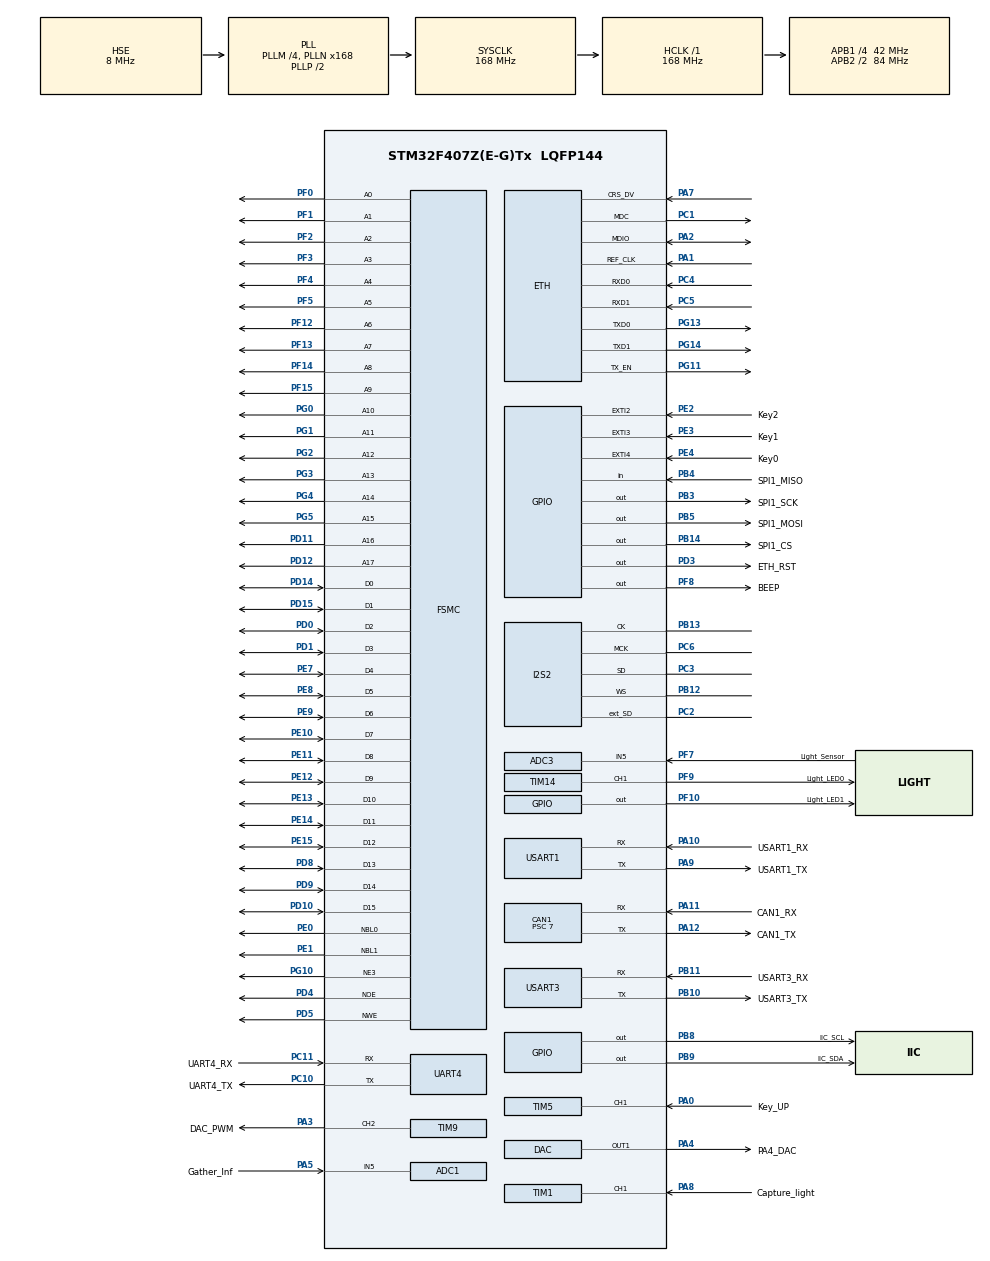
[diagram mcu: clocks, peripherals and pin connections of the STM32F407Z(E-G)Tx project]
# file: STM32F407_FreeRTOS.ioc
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ADC1.Channel-0\#ChannelRegularConversion=ADC_CHANNEL_5
ADC1.ClockPrescaler=ADC_CLOCK_SYNC_PCLK_DIV4
ADC1.ContinuousConvMode=ENABLE
ADC1.DMAContinuousRequests=ENABLE
ADC1.DataAlign=ADC_DATAALIGN_RIGHT
ADC1.DiscontinuousConvMode=DISABLE
ADC1.EOCSelection=ADC_EOC_SINGLE_CONV
ADC1.EnableAnalogWatchDog=false
ADC1.ExternalTrigConv=ADC_SOFTWARE_START
ADC1.ExternalTrigConvEdge=ADC_EXTERNALTRIGCONVEDGE_NONE
ADC1.InjNumberOfConversion=0
ADC1.NbrOfConversion=1
ADC1.NbrOfConversionFlag=1
ADC1.Rank-0\#ChannelRegularConversion=1
ADC1.Resolution=ADC_RESOLUTION_12B
ADC1.SamplingTime-0\#ChannelRegularConversion=ADC_SAMPLETIME_480CYCLES
ADC1.ScanConvMode=ENABLE
ADC1.master=1
ADC3.Channel-0\#ChannelRegularConversion=ADC_CHANNEL_5
ADC3.ClockPrescaler=ADC_CLOCK_SYNC_PCLK_DIV4
ADC3.ContinuousConvMode=ENABLE
ADC3.DMAContinuousRequests=ENABLE
ADC3.DataAlign=ADC_DATAALIGN_RIGHT
ADC3.DiscontinuousConvMode=DISABLE
ADC3.EOCSelection=ADC_EOC_SINGLE_CONV
ADC3.EnableAnalogWatchDog=false
ADC3.ExternalTrigConv=ADC_SOFTWARE_START
ADC3.ExternalTrigConvEdge=ADC_EXTERNALTRIGCONVEDGE_NONE
ADC3.InjNumberOfConversion=0
ADC3.NbrOfConversion=1
ADC3.NbrOfConversionFlag=1
ADC3.Rank-0\#ChannelRegularConversion=1
ADC3.Resolution=ADC_RESOLUTION_10B
ADC3.SamplingTime-0\#ChannelRegularConversion=ADC_SAMPLETIME_480CYCLES
ADC3.ScanConvMode=ENABLE
CAN1.ABOM=DISABLE
CAN1.AWUM=DISABLE
CAN1.BS1=CAN_BS1_5TQ
CAN1.BS2=CAN_BS2_6TQ
CAN1.CalculateTimeQuantum=166.66666666666669
CAN1.Mode=CAN_MODE_NORMAL
CAN1.NART=ENABLE
CAN1.Prescaler=7
CAN1.RFLM=DISABLE
CAN1.TTCM=DISABLE
CAN1.TXFP=DISABLE
DAC.DAC_OutputBuffer=DAC_OUTPUTBUFFER_DISABLE
Dma.ADC1.1.Direction=DMA_PERIPH_TO_MEMORY
Dma.ADC1.1.FIFOMode=DMA_FIFOMODE_DISABLE
Dma.ADC1.1.Instance=DMA2_Stream4
Dma.ADC1.1.MemDataAlignment=DMA_MDATAALIGN_HALFWORD
Dma.ADC1.1.MemInc=DMA_MINC_ENABLE
Dma.ADC1.1.Mode=DMA_NORMAL
Dma.ADC1.1.PeriphDataAlignment=DMA_PDATAALIGN_HALFWORD
Dma.ADC1.1.PeriphInc=DMA_PINC_DISABLE
Dma.ADC1.1.Priority=DMA_PRIORITY_LOW
Dma.ADC3.2.Direction=DMA_PERIPH_TO_MEMORY
Dma.ADC3.2.FIFOMode=DMA_FIFOMODE_DISABLE
Dma.ADC3.2.Instance=DMA2_Stream0
Dma.ADC3.2.MemDataAlignment=DMA_MDATAALIGN_HALFWORD
Dma.ADC3.2.MemInc=DMA_MINC_ENABLE
Dma.ADC3.2.Mode=DMA_CIRCULAR
Dma.ADC3.2.PeriphDataAlignment=DMA_PDATAALIGN_HALFWORD
Dma.ADC3.2.PeriphInc=DMA_PINC_DISABLE
Dma.ADC3.2.Priority=DMA_PRIORITY_LOW
Dma.DAC1.0.Direction=DMA_MEMORY_TO_PERIPH
Dma.DAC1.0.FIFOMode=DMA_FIFOMODE_DISABLE
Dma.DAC1.0.Instance=DMA1_Stream5
Dma.DAC1.0.MemDataAlignment=DMA_MDATAALIGN_WORD
Dma.DAC1.0.MemInc=DMA_MINC_ENABLE
Dma.DAC1.0.Mode=DMA_CIRCULAR
Dma.DAC1.0.PeriphDataAlignment=DMA_PDATAALIGN_WORD
Dma.DAC1.0.PeriphInc=DMA_PINC_DISABLE
Dma.DAC1.0.Priority=DMA_PRIORITY_LOW
Dma.I2S2_EXT_RX.4.Direction=DMA_PERIPH_TO_MEMORY
Dma.I2S2_EXT_RX.4.FIFOMode=DMA_FIFOMODE_DISABLE
Dma.I2S2_EXT_RX.4.Instance=DMA1_Stream3
Dma.I2S2_EXT_RX.4.MemDataAlignment=DMA_MDATAALIGN_HALFWORD
Dma.I2S2_EXT_RX.4.MemInc=DMA_MINC_ENABLE
Dma.I2S2_EXT_RX.4.Mode=DMA_CIRCULAR
Dma.I2S2_EXT_RX.4.PeriphDataAlignment=DMA_PDATAALIGN_HALFWORD
Dma.I2S2_EXT_RX.4.PeriphInc=DMA_PINC_DISABLE
Dma.I2S2_EXT_RX.4.Priority=DMA_PRIORITY_HIGH
Dma.Request0=DAC1
Dma.Request1=ADC1
Dma.Request2=ADC3
Dma.Request3=SPI2_TX
Dma.Request4=I2S2_EXT_RX
Dma.Request5=USART1_RX
Dma.Request6=USART3_RX
Dma.Request7=UART4_RX
Dma.SPI2_TX.3.Direction=DMA_MEMORY_TO_PERIPH
Dma.SPI2_TX.3.FIFOMode=DMA_FIFOMODE_DISABLE
Dma.SPI2_TX.3.Instance=DMA1_Stream4
Dma.SPI2_TX.3.MemDataAlignment=DMA_MDATAALIGN_HALFWORD
Dma.SPI2_TX.3.MemInc=DMA_MINC_ENABLE
Dma.SPI2_TX.3.Mode=DMA_CIRCULAR
Dma.SPI2_TX.3.PeriphDataAlignment=DMA_PDATAALIGN_HALFWORD
Dma.SPI2_TX.3.PeriphInc=DMA_PINC_DISABLE
Dma.SPI2_TX.3.Priority=DMA_PRIORITY_HIGH
Dma.UART4_RX.7.Direction=DMA_PERIPH_TO_MEMORY
Dma.UART4_RX.7.FIFOMode=DMA_FIFOMODE_DISABLE
Dma.UART4_RX.7.Instance=DMA1_Stream2
Dma.UART4_RX.7.MemDataAlignment=DMA_MDATAALIGN_BYTE
Dma.UART4_RX.7.MemInc=DMA_MINC_ENABLE
Dma.UART4_RX.7.Mode=DMA_NORMAL
Dma.UART4_RX.7.PeriphDataAlignment=DMA_PDATAALIGN_BYTE
Dma.UART4_RX.7.PeriphInc=DMA_PINC_DISABLE
Dma.UART4_RX.7.Priority=DMA_PRIORITY_LOW
Dma.USART1_RX.5.Direction=DMA_PERIPH_TO_MEMORY
Dma.USART1_RX.5.FIFOMode=DMA_FIFOMODE_DISABLE
Dma.USART1_RX.5.Instance=DMA2_Stream2
Dma.USART1_RX.5.MemDataAlignment=DMA_MDATAALIGN_BYTE
Dma.USART1_RX.5.MemInc=DMA_MINC_ENABLE
Dma.USART1_RX.5.Mode=DMA_NORMAL
Dma.USART1_RX.5.PeriphDataAlignment=DMA_PDATAALIGN_BYTE
Dma.USART1_RX.5.PeriphInc=DMA_PINC_DISABLE
Dma.USART1_RX.5.Priority=DMA_PRIORITY_LOW
Dma.USART3_RX.6.Direction=DMA_PERIPH_TO_MEMORY
Dma.USART3_RX.6.FIFOMode=DMA_FIFOMODE_DISABLE
Dma.USART3_RX.6.Instance=DMA1_Stream1
Dma.USART3_RX.6.MemDataAlignment=DMA_MDATAALIGN_BYTE
Dma.USART3_RX.6.MemInc=DMA_MINC_ENABLE
Dma.USART3_RX.6.Mode=DMA_NORMAL
Dma.USART3_RX.6.PeriphDataAlignment=DMA_PDATAALIGN_BYTE
Dma.USART3_RX.6.PeriphInc=DMA_PINC_DISABLE
Dma.USART3_RX.6.Priority=DMA_PRIORITY_LOW
ETH.AutoNegotiation=ETH_AUTONEGOTIATION_ENABLE
ETH.MediaInterface=ETH_MEDIA_INTERFACE_RMII
ETH.PHY_DUPLEX_STATUS=0x0010
ETH.PHY_Name_RMII=userPHY
ETH.PHY_SPEED_STATUS=0x0004
ETH.PHY_SR=0x1F
ETH.PHY_User_Name=LAN8720
ETH.PhyAddress=0
FREERTOS.Queues01=USMARTQueue,8,usmart_receiveSTR,0,Dynamic,NULL,NULL
FREERTOS.Tasks01=defaultTask,0,128,StartDefaultTask,Default,NULL,Dynamic,NULL,NULL;ThreadTask02,0,128,USART1ManageFuc,Default,NULL,Dynamic,NULL,NULL;ThreadTask03,-3,128,USMARTManageFuc,Default,NULL,Dynamic,NULL,NULL;ThreadTask04,-3,128,J1939ManageFuc,Default,NULL,Dynamic,NULL,NULL;ThreadTask05,-3,128,LwipManageFuc,Default,NULL,Dynamic,NULL,NULL
FSMC.AddressSetupTime1=0
FSMC.BusTurnAroundDuration1=0
FSMC.DataSetupTime1=6
FSMC.WriteOperation1=FSMC_WRITE_OPERATION_ENABLE
I2S2.AudioFreq=I2S_AUDIOFREQ_8K
I2S2.CPOL=I2S_CPOL_LOW
I2S2.DataFormat=I2S_DATAFORMAT_24B
I2S2.ErrorAudioFreq=-0.12 %
I2S2.FullDuplexMode=I2S_FULLDUPLEXMODE_ENABLE
I2S2.Instance=SPI$Index
I2S2.RealAudioFreq=7.99 KHz
I2S2.VirtualMode=I2S_MODE_MASTER
LWIP.GATEWAY_ADDRESS=192.168.000.001
LWIP.IP_ADDRESS=192.168.000.030
LWIP.LWIP_DHCP=0
LWIP.LWIP_IPV6=0
LWIP.LWIP_UDP=1
LWIP.MEMP_NUM_UDP_PCB=4
LWIP.MEM_SIZE=1600
LWIP.NETMASK_ADDRESS=255.255.255.000
LWIP.TCP_WND=2144
LWIP.Version=v2.0.3_Cube
Mcu.Family=STM32F4
Mcu.Name=STM32F407Z(E-G)Tx
Mcu.Package=LQFP144
NVIC.CAN1_RX0_IRQn=true\:5\:0\:false\:false\:true\:true\:true
NVIC.DMA1_Stream1_IRQn=true\:5\:0\:false\:false\:true\:true\:false
NVIC.DMA1_Stream2_IRQn=true\:10\:0\:true\:false\:true\:true\:false
NVIC.DMA1_Stream3_IRQn=true\:5\:0\:false\:false\:true\:true\:false
NVIC.DMA1_Stream4_IRQn=true\:5\:0\:false\:false\:true\:true\:false
NVIC.DMA1_Stream5_IRQn=true\:5\:0\:false\:false\:true\:true\:false
NVIC.DMA2_Stream0_IRQn=true\:5\:0\:false\:false\:true\:true\:false
NVIC.DMA2_Stream2_IRQn=true\:5\:0\:false\:false\:true\:true\:false
NVIC.DMA2_Stream4_IRQn=true\:5\:0\:false\:false\:true\:true\:false
NVIC.ETH_IRQn=true\:12\:0\:true\:false\:true\:true\:false
NVIC.EXTI2_IRQn=true\:12\:0\:true\:false\:true\:true\:true
NVIC.EXTI3_IRQn=true\:12\:0\:true\:false\:true\:true\:true
NVIC.EXTI4_IRQn=true\:12\:0\:true\:false\:true\:true\:true
NVIC.HASH_RNG_IRQn=true\:15\:0\:true\:false\:true\:true\:true
NVIC.PriorityGroup=NVIC_PRIORITYGROUP_4
NVIC.RTC_Alarm_IRQn=true\:15\:0\:true\:false\:true\:true\:true
NVIC.TIM1_CC_IRQn=true\:6\:0\:true\:false\:true\:true\:true
NVIC.TIM1_UP_TIM10_IRQn=true\:6\:0\:true\:false\:true\:true\:true
NVIC.TIM2_IRQn=true\:6\:0\:true\:false\:true\:true\:true
NVIC.TIM3_IRQn=true\:0\:0\:false\:false\:true\:false\:false
NVIC.TIM4_IRQn=true\:7\:0\:true\:false\:true\:true\:true
NVIC.TIM5_IRQn=true\:14\:0\:true\:false\:true\:true\:true
NVIC.TIM7_IRQn=true\:5\:0\:true\:false\:true\:true\:true
NVIC.TIM8_TRG_COM_TIM14_IRQn=true\:5\:0\:false\:false\:true\:true\:true
NVIC.TimeBase=TIM3_IRQn
NVIC.TimeBaseIP=TIM3
NVIC.UART4_IRQn=true\:13\:0\:true\:false\:true\:true\:true
NVIC.USART1_IRQn=true\:6\:0\:true\:false\:true\:true\:true
NVIC.USART3_IRQn=true\:7\:0\:true\:false\:true\:true\:true
PA0-WKUP.GPIO_Label=Key_UP
PA0-WKUP.GPIO_PuPd=GPIO_NOPULL
PA0-WKUP.GPIO_Speed=GPIO_SPEED_FREQ_LOW
PA0-WKUP.Signal=S_TIM5_CH1
PA1.Mode=RMII
PA1.Signal=ETH_REF_CLK
PA10.GPIO_Label=USART1_RX
PA10.GPIO_Speed=GPIO_SPEED_FREQ_HIGH
PA10.Mode=Asynchronous
PA10.Signal=USART1_RX
PA11.GPIO_Label=CAN1_RX
PA11.GPIO_PuPd=GPIO_PULLUP
PA11.GPIO_Speed=GPIO_SPEED_FREQ_HIGH
PA11.Mode=Master
PA11.Signal=CAN1_RX
PA12.GPIO_Label=CAN1_TX
PA12.GPIO_PuPd=GPIO_PULLUP
PA12.GPIO_Speed=GPIO_SPEED_FREQ_HIGH
PA12.Mode=Master
PA12.Signal=CAN1_TX
PA13.Mode=Serial_Wire
PA13.Signal=SYS_JTMS-SWDIO
PA14.Mode=Serial_Wire
PA14.Signal=SYS_JTCK-SWCLK
PA2.Mode=RMII
PA2.Signal=ETH_MDIO
PA3.GPIO_Label=DAC_PWM
PA3.Signal=S_TIM9_CH2
PA4.GPIO_Label=PA4_DAC
PA4.Signal=SharedAnalog_PA4
PA5.GPIO_Label=Gather_Inf
PA5.Signal=SharedAnalog_PA5
PA7.Mode=RMII
PA7.Signal=ETH_CRS_DV
PA8.GPIO_Label=Capture_light
PA8.GPIO_PuPd=GPIO_PULLUP
PA8.GPIO_Speed=GPIO_SPEED_FREQ_HIGH
PA8.Signal=S_TIM1_CH1
PA9.GPIO_Label=USART1_TX
PA9.GPIO_Speed=GPIO_SPEED_FREQ_HIGH
PA9.Mode=Asynchronous
PA9.Signal=USART1_TX
PB10.GPIO_Label=USART3_TX
PB10.GPIO_Speed=GPIO_SPEED_FREQ_HIGH
PB10.Mode=Asynchronous
PB10.Signal=USART3_TX
PB11.GPIO_Label=USART3_RX
PB11.GPIO_Speed=GPIO_SPEED_FREQ_HIGH
PB11.Mode=Asynchronous
PB11.Signal=USART3_RX
PB12.GPIO_PuPd=GPIO_PULLUP
PB12.GPIO_Speed=GPIO_SPEED_FREQ_HIGH
PB12.Mode=Full_Duplex_Master
PB12.Signal=I2S2_WS
PB13.GPIO_PuPd=GPIO_PULLUP
PB13.GPIO_Speed=GPIO_SPEED_FREQ_HIGH
PB13.Mode=Full_Duplex_Master
PB13.Signal=I2S2_CK
PB14.GPIO_Label=SPI1_CS
PB14.GPIO_PuPd=GPIO_PULLUP
PB14.GPIO_Speed=GPIO_SPEED_FREQ_HIGH
PB14.Signal=GPIO_Output
PB3.GPIO_Label=SPI1_SCK
PB3.GPIO_PuPd=GPIO_PULLUP
PB3.GPIO_Speed=GPIO_SPEED_FREQ_HIGH
PB3.Signal=GPIO_Output
PB4.GPIO_Label=SPI1_MISO
PB4.GPIO_PuPd=GPIO_PULLUP
PB4.Signal=GPIO_Input
PB5.GPIO_Label=SPI1_MOSI
PB5.GPIO_PuPd=GPIO_PULLUP
PB5.GPIO_Speed=GPIO_SPEED_FREQ_HIGH
PB5.Signal=GPIO_Output
PB8.GPIO_Label=IIC_SCL
PB8.GPIO_ModeDefaultOutputPP=GPIO_MODE_OUTPUT_PP
PB8.GPIO_PuPd=GPIO_PULLUP
PB8.GPIO_Speed=GPIO_SPEED_FREQ_HIGH
PB8.Signal=GPIO_Output
PB9.GPIO_Label=IIC_SDA
PB9.GPIO_PuPd=GPIO_PULLUP
PB9.GPIO_Speed=GPIO_SPEED_FREQ_HIGH
PB9.Signal=GPIO_Output
PC1.Mode=RMII
PC1.Signal=ETH_MDC
PC10.GPIO_Label=UART4_TX
PC10.GPIO_Speed=GPIO_SPEED_FREQ_HIGH
PC10.Mode=Asynchronous
PC10.Signal=UART4_TX
PC11.GPIO_Label=UART4_RX
PC11.GPIO_Speed=GPIO_SPEED_FREQ_HIGH
PC11.Mode=Asynchronous
PC11.Signal=UART4_RX
PC14-OSC32_IN.Mode=LSE-External-Oscillator
PC14-OSC32_IN.Signal=RCC_OSC32_IN
PC15-OSC32_OUT.Mode=LSE-External-Oscillator
PC15-OSC32_OUT.Signal=RCC_OSC32_OUT
PC2.Mode=Full_Duplex_Master
PC2.Signal=I2S2_ext_SD
PC3.Mode=Full_Duplex_Master
PC3.Signal=I2S2_SD
PC4.Mode=RMII
PC4.Signal=ETH_RXD0
PC5.Mode=RMII
PC5.Signal=ETH_RXD1
PC6.Mode=Master_Clock_Activated
PC6.Signal=I2S2_MCK
PD0.Signal=FSMC_D2_DA2
PD1.Signal=FSMC_D3_DA3
PD10.Signal=FSMC_D15_DA15
PD11.Signal=FSMC_A16_CLE
PD12.Signal=FSMC_A17_ALE
PD14.Signal=FSMC_D0_DA0
PD15.Signal=FSMC_D1_DA1
PD3.GPIO_Label=ETH_RST
PD3.Signal=GPIO_Output
PD4.Signal=FSMC_NOE
PD5.Signal=FSMC_NWE
PD8.Signal=FSMC_D13_DA13
PD9.Signal=FSMC_D14_DA14
PE0.Signal=FSMC_NBL0
PE1.Signal=FSMC_NBL1
PE10.Signal=FSMC_D7_DA7
PE11.Signal=FSMC_D8_DA8
PE12.Signal=FSMC_D9_DA9
PE13.Signal=FSMC_D10_DA10
PE14.Signal=FSMC_D11_DA11
PE15.Signal=FSMC_D12_DA12
PE2.GPIO_Label=Key2
PE2.GPIO_ModeDefaultEXTI=GPIO_MODE_IT_FALLING
PE2.GPIO_PuPd=GPIO_PULLUP
PE2.Signal=GPXTI2
PE3.GPIO_Label=Key1
PE3.GPIO_ModeDefaultEXTI=GPIO_MODE_IT_FALLING
PE3.GPIO_PuPd=GPIO_PULLUP
PE3.Signal=GPXTI3
PE4.GPIO_Label=Key0
PE4.GPIO_ModeDefaultEXTI=GPIO_MODE_IT_FALLING
PE4.GPIO_PuPd=GPIO_PULLUP
PE4.Signal=GPXTI4
PE7.Signal=FSMC_D4_DA4
PE8.Signal=FSMC_D5_DA5
PE9.Signal=FSMC_D6_DA6
PF0.Signal=FSMC_A0
PF1.Signal=FSMC_A1
PF10.GPIO_Label=Light_LED1
PF10.GPIO_PuPd=GPIO_PULLDOWN
PF10.Signal=GPIO_Output
PF12.Signal=FSMC_A6
PF13.Signal=FSMC_A7
PF14.Signal=FSMC_A8
PF15.Signal=FSMC_A9
PF2.Signal=FSMC_A2
PF3.Signal=FSMC_A3
PF4.Signal=FSMC_A4
PF5.Signal=FSMC_A5
PF7.GPIO_Label=Light_Sensor
PF7.Signal=SharedAnalog_PF7
PF8.GPIO_Label=BEEP
PF8.GPIO_Speed=GPIO_SPEED_FREQ_HIGH
PF8.Signal=GPIO_Output
PF9.GPIO_Label=Light_LED0
PF9.GPIO_PuPd=GPIO_PULLDOWN
PF9.Signal=S_TIM14_CH1
PG0.Signal=FSMC_A10
PG1.Signal=FSMC_A11
PG10.Mode=NorPsramChipSelect3_1
PG10.Signal=FSMC_NE3
PG11.Mode=RMII
PG11.Signal=ETH_TX_EN
PG13.Mode=RMII
PG13.Signal=ETH_TXD0
PG14.Mode=RMII
PG14.Signal=ETH_TXD1
PG2.Signal=FSMC_A12
PG3.Signal=FSMC_A13
PG4.Signal=FSMC_A14
PG5.Signal=FSMC_A15
PH0-OSC_IN.Mode=HSE-External-Oscillator
PH0-OSC_IN.Signal=RCC_OSC_IN
PH1-OSC_OUT.Mode=HSE-External-Oscillator
PH1-OSC_OUT.Signal=RCC_OSC_OUT
ProjectManager.HeapSize=0x200
ProjectManager.StackSize=0x400
ProjectManager.TargetToolchain=EWARM V8
RCC.48MHZClocksFreq_Value=48000000
RCC.AHBFreq_Value=168000000
RCC.APB1CLKDivider=RCC_HCLK_DIV4
RCC.APB1Freq_Value=42000000
RCC.APB1TimFreq_Value=84000000
RCC.APB2CLKDivider=RCC_HCLK_DIV2
RCC.APB2Freq_Value=84000000
RCC.APB2TimFreq_Value=168000000
RCC.CortexFreq_Value=168000000
RCC.HCLKFreq_Value=168000000
RCC.HSE_VALUE=8000000
RCC.HSI_VALUE=16000000
RCC.PLLI2SN=135
RCC.PLLI2SR=6
RCC.PLLM=4
RCC.PLLN=168
RCC.PLLQ=7
RCC.PLLSourceVirtual=RCC_PLLSOURCE_HSE
RCC.RCC_RTC_Clock_Source=RCC_RTCCLKSOURCE_LSI
RCC.RCC_RTC_Clock_SourceVirtual=RCC_RTCCLKSOURCE_LSE
RCC.SYSCLKFreq_VALUE=168000000
RCC.SYSCLKSource=RCC_SYSCLKSOURCE_PLLCLK
RCC.VCOOutputFreq_Value=336000000
RTC.Alarm=RTC_ALARM_A
RTC.AlarmDateWeekDaySel=RTC_ALARMDATEWEEKDAYSEL_WEEKDAY
RTC.AlarmSubSecondMask=RTC_ALARMSUBSECONDMASK_NONE
RTC.Date=16
RTC.Hours=22
RTC.Hours_A=15
RTC.Minutes=42
RTC.Minutes_A=18
RTC.Seconds=55
RTC.Seconds_A=23
RTC.WeekDay=RTC_WEEKDAY_WEDNESDAY
RTC.Year=21
SH.FSMC_A0.0=FSMC_A0,18b-a1
SH.FSMC_A1.0=FSMC_A1,18b-a1
SH.FSMC_A10.0=FSMC_A10,18b-a1
SH.FSMC_A11.0=FSMC_A11,18b-a1
SH.FSMC_A12.0=FSMC_A12,18b-a1
SH.FSMC_A13.0=FSMC_A13,18b-a1
SH.FSMC_A14.0=FSMC_A14,18b-a1
SH.FSMC_A15.0=FSMC_A15,18b-a1
SH.FSMC_A16_CLE.0=FSMC_A16,18b-a1
SH.FSMC_A17_ALE.0=FSMC_A17,18b-a1
SH.FSMC_A2.0=FSMC_A2,18b-a1
SH.FSMC_A3.0=FSMC_A3,18b-a1
SH.FSMC_A4.0=FSMC_A4,18b-a1
SH.FSMC_A5.0=FSMC_A5,18b-a1
SH.FSMC_A6.0=FSMC_A6,18b-a1
SH.FSMC_A7.0=FSMC_A7,18b-a1
SH.FSMC_A8.0=FSMC_A8,18b-a1
SH.FSMC_A9.0=FSMC_A9,18b-a1
SH.FSMC_D0_DA0.0=FSMC_D0,16b-d1
SH.FSMC_D10_DA10.0=FSMC_D10,16b-d1
SH.FSMC_D11_DA11.0=FSMC_D11,16b-d1
SH.FSMC_D12_DA12.0=FSMC_D12,16b-d1
SH.FSMC_D13_DA13.0=FSMC_D13,16b-d1
SH.FSMC_D14_DA14.0=FSMC_D14,16b-d1
SH.FSMC_D15_DA15.0=FSMC_D15,16b-d1
SH.FSMC_D1_DA1.0=FSMC_D1,16b-d1
SH.FSMC_D2_DA2.0=FSMC_D2,16b-d1
SH.FSMC_D3_DA3.0=FSMC_D3,16b-d1
SH.FSMC_D4_DA4.0=FSMC_D4,16b-d1
SH.FSMC_D5_DA5.0=FSMC_D5,16b-d1
SH.FSMC_D6_DA6.0=FSMC_D6,16b-d1
SH.FSMC_D7_DA7.0=FSMC_D7,16b-d1
SH.FSMC_D8_DA8.0=FSMC_D8,16b-d1
SH.FSMC_D9_DA9.0=FSMC_D9,16b-d1
SH.FSMC_NBL0.0=FSMC_NBL0,2ByteEnable1
SH.FSMC_NBL1.0=FSMC_NBL1,2ByteEnable1
SH.FSMC_NOE.0=FSMC_NOE,Sram1
SH.FSMC_NWE.0=FSMC_NWE,Sram1
SH.S_TIM14_CH1.0=TIM14_CH1,PWM Generation1 CH1
SH.S_TIM1_CH1.0=TIM1_CH1,Input_Capture1_from_TI1
SH.S_TIM5_CH1.0=TIM5_CH1,Input_Capture1_from_TI1
SH.S_TIM9_CH2.0=TIM9_CH2,PWM Generation2 CH2
SH.SharedAnalog_PA4.0=GPIO_Analog
SH.SharedAnalog_PA4.1=DAC_OUT1,DAC_OUT1
SH.SharedAnalog_PA5.0=GPIO_Analog
SH.SharedAnalog_PA5.1=ADC1_IN5,IN5
SH.SharedAnalog_PF7.0=GPIO_Analog
SH.SharedAnalog_PF7.1=ADC3_IN5,IN5
TIM1.Channel-Input_Capture1_from_TI1=TIM_CHANNEL_1
TIM1.ICFilter_CH1=0x03
TIM1.Period=10000
TIM1.Prescaler=179
TIM14.Channel=TIM_CHANNEL_1
TIM14.OCPolarity_1=TIM_OCPOLARITY_LOW
TIM14.Period=500
TIM14.Prescaler=42
TIM2.Channel-Input_Capture1_from_TI1=TIM_CHANNEL_1
TIM2.Period=0xFFFFFFFF
TIM2.Prescaler=1
TIM2.TIM_MasterOutputTrigger=TIM_TRGO_UPDATE
TIM4.Period=1000
TIM4.Prescaler=8400-1
TIM5.Channel-Input_Capture1_from_TI1=TIM_CHANNEL_1
TIM5.Period=0xFFFFFFFF
TIM5.Prescaler=84
TIM5.TIM_MasterOutputTrigger=TIM_TRGO_UPDATE
TIM7.Period=1
TIM7.Prescaler=84-1
TIM9.Channel-PWM\ Generation2\ CH2=TIM_CHANNEL_2
TIM9.Period=255
TIM9.Prescaler=1
UART4.VirtualMode=Asynchronous
USART1.OverSampling=UART_OVERSAMPLING_16
USART1.VirtualMode=VM_ASYNC
USART3.VirtualMode=VM_ASYNC
VP_FREERTOS_VS_ENABLE.Mode=Enabled
VP_LWIP_VS_Enabled.Mode=Enabled
VP_RNG_VS_RNG.Mode=RNG_Activate
VP_RTC_VS_RTC_Activate.Mode=RTC_Enabled
VP_RTC_VS_RTC_Alarm_A_Intern.Mode=Alarm A
VP_RTC_VS_RTC_Calendar.Mode=RTC_Calendar
VP_SYS_VS_tim3.Mode=TIM3
VP_TIM14_VS_ClockSourceINT.Mode=Enable_Timer
VP_TIM1_VS_ClockSourceINT.Mode=Internal
VP_TIM1_VS_ClockSourceITR.Mode=TriggerSource_ITR0
VP_TIM2_VS_ClockSourceINT.Mode=Internal
VP_TIM2_VS_ClockSourceITR.Mode=TriggerSource_ITR0
VP_TIM4_VS_ClockSourceINT.Mode=Internal
VP_TIM5_VS_ClockSourceINT.Mode=Internal
VP_TIM5_VS_ClockSourceITR.Mode=TriggerSource_ITR0
VP_TIM7_VS_ClockSourceINT.Mode=Enable_Timer
board=custom

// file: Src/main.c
/**
  ******************************************************************************
  * @file           : main.c
  * @brief          : Main program body
  ******************************************************************************
  * This notice applies to any and all portions of this file
  * that are not between comment pairs USER CODE BEGIN and
  * USER CODE END. Other portions of this file, whether
  * inserted by the user or by software development tools
  * are owned by their respective copyright owners.
  *
  * Copyright (c) 2021 STMicroelectronics International N.V.
  * All rights reserved.
  *
  * Redistribution and use in source and binary forms, with or without
  * modification, are permitted, provided that the following conditions are met:
  *
  * 1. Redistribution of source code must retain the above copyright notice,
  *    this list of conditions and the following disclaimer.
  * 2. Redistributions in binary form must reproduce the above copyright notice,
  *    this list of conditions and the following disclaimer in the documentation
  *    and/or other materials provided with the distribution.
  * 3. Neither the name of STMicroelectronics nor the names of other
  *    contributors to this software may be used to endorse or promote products
  *    derived from this software without specific written permission.
  * 4. This software, including modifications and/or derivative works of this
  *    software, must execute solely and exclusively on microcontroller or
  *    microprocessor devices manufactured by or for STMicroelectronics.
  * 5. Redistribution and use of this software other than as permitted under
  *    this license is void and will automatically terminate your rights under
  *    this license.
  *
  * THIS SOFTWARE IS PROVIDED BY STMICROELECTRONICS AND CONTRIBUTORS "AS IS"
  * AND ANY EXPRESS, IMPLIED OR STATUTORY WARRANTIES, INCLUDING, BUT NOT
  * LIMITED TO, THE IMPLIED WARRANTIES OF MERCHANTABILITY, FITNESS FOR A
  * PARTICULAR PURPOSE AND NON-INFRINGEMENT OF THIRD PARTY INTELLECTUAL PROPERTY
  * RIGHTS ARE DISCLAIMED TO THE FULLEST EXTENT PERMITTED BY LAW. IN NO EVENT
  * SHALL STMICROELECTRONICS OR CONTRIBUTORS BE LIABLE FOR ANY DIRECT, INDIRECT,
  * INCIDENTAL, SPECIAL, EXEMPLARY, OR CONSEQUENTIAL DAMAGES (INCLUDING, BUT NOT
  * LIMITED TO, PROCUREMENT OF SUBSTITUTE GOODS OR SERVICES; LOSS OF USE, DATA,
  * OR PROFITS; OR BUSINESS INTERRUPTION) HOWEVER CAUSED AND ON ANY THEORY OF
  * LIABILITY, WHETHER IN CONTRACT, STRICT LIABILITY, OR TORT (INCLUDING
  * NEGLIGENCE OR OTHERWISE) ARISING IN ANY WAY OUT OF THE USE OF THIS SOFTWARE,
  * EVEN IF ADVISED OF THE POSSIBILITY OF SUCH DAMAGE.
  *
  ******************************************************************************
  */
#include "main.h"
#include "stm32f4xx_hal.h"
#include "cmsis_os.h"
#include "adc.h"
#include "can.h"
#include "dac.h"
#include "dma.h"
#include "i2s.h"
#include "lwip.h"
#include "rng.h"
#include "rtc.h"
#include "tim.h"
#include "usart.h"
#include "gpio.h"
#include "fsmc.h"

/* USER CODE BEGIN Includes */
#include "APP_USART.h"
#include "led.h"
#include "app_rng.h"
#include "remote.h"
/* USER CODE END Includes */

/* USER CODE BEGIN PV */
/* Private variables ---------------------------------------------------------*/
extern volatile uint32_t tick_time7_counter;
extern volatile uint8_t		TIM5CH1_CAPTURE_STA;	// 输入捕获状�??
extern volatile uint32_t	TIM5CH1_CAPTURE_VAL;		// 输入捕获�???(TIM2/TIM5�???32位的定时器所以这里定义为uint32_t)
/* USER CODE END PV */

void SystemClock_Config(void);
void MX_FREERTOS_Init(void);

/* USER CODE BEGIN PFP */
/* Private function prototypes -----------------------------------------------*/

/* USER CODE END PFP */

int main(void)
{

  /* MCU Configuration----------------------------------------------------------*/

  /* Reset of all peripherals, Initializes the Flash interface and the Systick. */
  HAL_Init();

  /* Configure the system clock */
  SystemClock_Config();

  /* Initialize all configured peripherals */
  MX_GPIO_Init();
  MX_DMA_Init();
  MX_USART1_UART_Init();
  MX_TIM7_Init();
  MX_TIM14_Init();
  MX_TIM5_Init();
  MX_TIM2_Init();
  MX_TIM4_Init();
  MX_RTC_Init();
  MX_CAN1_Init();
  MX_RNG_Init();
  MX_ADC3_Init();
  MX_ADC1_Init();
  MX_DAC_Init();
  MX_TIM9_Init();
  MX_TIM1_Init();
  MX_FSMC_Init();
  MX_I2S2_Init();
  MX_USART3_UART_Init();
  MX_UART4_Init();

  /* Call init function for freertos objects (in freertos.c) */
  MX_FREERTOS_Init();

  /* Start scheduler */
  osKernelStart();

  /* We should never get here as control is now taken by the scheduler */

  /* Infinite loop */
  while (1)
  {

  }

}

void SystemClock_Config(void)
{

  RCC_OscInitTypeDef RCC_OscInitStruct;
  RCC_ClkInitTypeDef RCC_ClkInitStruct;
  RCC_PeriphCLKInitTypeDef PeriphClkInitStruct;

    /**Configure the main internal regulator output voltage
    */
  __HAL_RCC_PWR_CLK_ENABLE();

  __HAL_PWR_VOLTAGESCALING_CONFIG(PWR_REGULATOR_VOLTAGE_SCALE1);

    /**Initializes the CPU, AHB and APB busses clocks
    */
  RCC_OscInitStruct.OscillatorType = RCC_OSCILLATORTYPE_LSI|RCC_OSCILLATORTYPE_HSE;
  RCC_OscInitStruct.HSEState = RCC_HSE_ON;
  RCC_OscInitStruct.LSIState = RCC_LSI_ON;
  RCC_OscInitStruct.PLL.PLLState = RCC_PLL_ON;
  RCC_OscInitStruct.PLL.PLLSource = RCC_PLLSOURCE_HSE;
  RCC_OscInitStruct.PLL.PLLM = 4;
  RCC_OscInitStruct.PLL.PLLN = 168;
  RCC_OscInitStruct.PLL.PLLP = RCC_PLLP_DIV2;
  RCC_OscInitStruct.PLL.PLLQ = 7;
  if (HAL_RCC_OscConfig(&RCC_OscInitStruct) != HAL_OK)
  {
    _Error_Handler(__FILE__, __LINE__);
  }

    /**Initializes the CPU, AHB and APB busses clocks
    */
  RCC_ClkInitStruct.ClockType = RCC_CLOCKTYPE_HCLK|RCC_CLOCKTYPE_SYSCLK
                              |RCC_CLOCKTYPE_PCLK1|RCC_CLOCKTYPE_PCLK2;
  RCC_ClkInitStruct.SYSCLKSource = RCC_SYSCLKSOURCE_PLLCLK;
  RCC_ClkInitStruct.AHBCLKDivider = RCC_SYSCLK_DIV1;
  RCC_ClkInitStruct.APB1CLKDivider = RCC_HCLK_DIV4;
  RCC_ClkInitStruct.APB2CLKDivider = RCC_HCLK_DIV2;

  if (HAL_RCC_ClockConfig(&RCC_ClkInitStruct, FLASH_LATENCY_5) != HAL_OK)
  {
    _Error_Handler(__FILE__, __LINE__);
  }

  PeriphClkInitStruct.PeriphClockSelection = RCC_PERIPHCLK_I2S|RCC_PERIPHCLK_RTC;
  PeriphClkInitStruct.PLLI2S.PLLI2SN = 135;
  PeriphClkInitStruct.PLLI2S.PLLI2SR = 6;
  PeriphClkInitStruct.RTCClockSelection = RCC_RTCCLKSOURCE_LSI;
  if (HAL_RCCEx_PeriphCLKConfig(&PeriphClkInitStruct) != HAL_OK)
  {
    _Error_Handler(__FILE__, __LINE__);
  }

    /**Configure the Systick interrupt time
    */
  HAL_SYSTICK_Config(HAL_RCC_GetHCLKFreq()/1000);

    /**Configure the Systick
    */
  HAL_SYSTICK_CLKSourceConfig(SYSTICK_CLKSOURCE_HCLK);

  /* SysTick_IRQn interrupt configuration */
  HAL_NVIC_SetPriority(SysTick_IRQn, 15, 0);
}

/* USER CODE BEGIN 4 */
void HAL_GPIO_EXTI_Callback(uint16_t GPIO_Pin){
  if(GPIO_Pin == Key0_Pin){
    log_printf("[INFO]Rand Number:%d\r\n", RNG_Get_RandomNum());
    log_printf("[INFO] Key0_Pin \r\n");
    LED0_Toogle;
  }
  if(GPIO_Pin == Key1_Pin){
    log_printf("[INFO] Key1_Pin \r\n");
    LED1_Toggle;
  }
  if(GPIO_Pin == Key2_Pin){
    log_printf("[INFO] Key2_Pin \r\n");
    delay_ms(1000);
  }
  if(GPIO_Pin == Key_UP_Pin){
    log_printf("[INFO] Key_UP_Pin \r\n");
    delay_ms(1000);
  }
}
/* USER CODE END 4 */

void HAL_TIM_PeriodElapsedCallback(TIM_HandleTypeDef *htim)
{
  if (htim->Instance == TIM3) {
    HAL_IncTick();
  }
  /* USER CODE BEGIN Callback 1 */
  if(htim->Instance == TIM7)
  {
    tick_time7_counter++;
  }
  if (htim->Instance == TIM5)	// 判断是定时器5发生中断
  {
    if ((TIM5CH1_CAPTURE_STA & 0x80) == 0) // 还未成功捕获
    {
      if (TIM5CH1_CAPTURE_STA & 0x40)		   // 捕获到高电平
      {
        if ( (TIM5CH1_CAPTURE_STA & 0x3f) == 0x3f )		// 如果高电平太�???  做溢出处�???
        {
          TIM5CH1_CAPTURE_STA |= 0x80;				// 标记成功捕获了一�???
          TIM5CH1_CAPTURE_VAL = 0xffffffff;
        }else{
          TIM5CH1_CAPTURE_STA++;		// 若没有溢�???, 就只让TIM5CH1_CAPTURE_STA自加就ok
        }
      }
    }
  }
  if(htim->Instance == TIM1){
    if(RmtSta&0x80)//??????????
    {
      RmtSta&=~0X10;						//????????????
      if((RmtSta&0X0F)==0X00)RmtSta|=1<<6;//?????????????????
      if((RmtSta&0X0F)<14){
        RmtSta++;
      }else{
        RmtSta&=~(1<<7);//??????
        RmtSta&=0XF0;	//?????
      }
    }
  }
  /* USER CODE END Callback 1 */
}

void _Error_Handler(char *file, int line)
{
  /* USER CODE BEGIN Error_Handler_Debug */
  /* User can add his own implementation to report the HAL error return state */
  while(1)
  {
    log_printf("[INFO]Error Occur file:%s, line:%s \r\n",file,line);
  }
  /* USER CODE END Error_Handler_Debug */
}

/************************ (C) COPYRIGHT STMicroelectronics *****END OF FILE****/

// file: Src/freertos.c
/* USER CODE BEGIN Header */
/**
  ******************************************************************************
  * File Name          : freertos.c
  * Description        : Code for freertos applications
  ******************************************************************************
  * This notice applies to any and all portions of this file
  * that are not between comment pairs USER CODE BEGIN and
  * USER CODE END. Other portions of this file, whether
  * inserted by the user or by software development tools
  * are owned by their respective copyright owners.
  *
  * Copyright (c) 2020 STMicroelectronics International N.V.
  * All rights reserved.
  *
  * Redistribution and use in source and binary forms, with or without
  * modification, are permitted, provided that the following conditions are met:
  *
  * 1. Redistribution of source code must retain the above copyright notice,
  *    this list of conditions and the following disclaimer.
  * 2. Redistributions in binary form must reproduce the above copyright notice,
  *    this list of conditions and the following disclaimer in the documentation
  *    and/or other materials provided with the distribution.
  * 3. Neither the name of STMicroelectronics nor the names of other
  *    contributors to this software may be used to endorse or promote products
  *    derived from this software without specific written permission.
  * 4. This software, including modifications and/or derivative works of this
  *    software, must execute solely and exclusively on microcontroller or
  *    microprocessor devices manufactured by or for STMicroelectronics.
  * 5. Redistribution and use of this software other than as permitted under
  *    this license is void and will automatically terminate your rights under
  *    this license.
  *
  * THIS SOFTWARE IS PROVIDED BY STMICROELECTRONICS AND CONTRIBUTORS "AS IS"
  * AND ANY EXPRESS, IMPLIED OR STATUTORY WARRANTIES, INCLUDING, BUT NOT
  * LIMITED TO, THE IMPLIED WARRANTIES OF MERCHANTABILITY, FITNESS FOR A
  * PARTICULAR PURPOSE AND NON-INFRINGEMENT OF THIRD PARTY INTELLECTUAL PROPERTY
  * RIGHTS ARE DISCLAIMED TO THE FULLEST EXTENT PERMITTED BY LAW. IN NO EVENT
  * SHALL STMICROELECTRONICS OR CONTRIBUTORS BE LIABLE FOR ANY DIRECT, INDIRECT,
  * INCIDENTAL, SPECIAL, EXEMPLARY, OR CONSEQUENTIAL DAMAGES (INCLUDING, BUT NOT
  * LIMITED TO, PROCUREMENT OF SUBSTITUTE GOODS OR SERVICES; LOSS OF USE, DATA,
  * OR PROFITS; OR BUSINESS INTERRUPTION) HOWEVER CAUSED AND ON ANY THEORY OF
  * LIABILITY, WHETHER IN CONTRACT, STRICT LIABILITY, OR TORT (INCLUDING
  * NEGLIGENCE OR OTHERWISE) ARISING IN ANY WAY OUT OF THE USE OF THIS SOFTWARE,
  * EVEN IF ADVISED OF THE POSSIBILITY OF SUCH DAMAGE.
  *
  ******************************************************************************
  */
/* USER CODE END Header */

#include "FreeRTOS.h"
#include "task.h"
#include "main.h"
#include "cmsis_os.h"

/* USER CODE BEGIN Includes */
#include "stm32f4xx.h"
#include "led.h"
#include "beep.h"
#include "APP_USART.h"
#include "tim.h"
#include "pwm.h"
#include "inputCapture.h"
#include "tpad.h"
#include "usmart_receiveFromUsart.h"
#include "sys_stdlib.h"
#include "log_printf.h"
#include "app_rtc.h"
#include "J1939x.h"
#include "app_can.h"
#include "app_adc.h"
#include "w25qxx.h"
#include "BMS.h"
#include "remote_control.h"
#include "XMRAM.h"
#include "BMS_BMS.h"
#include "lwip_comm.h"
#include "tcp_client.h"
/* USER CODE END Includes */

/* USER CODE BEGIN PTD */
extern USMART_RECV_STR usmart_receiveSTR;
/* USER CODE END PTD */

osThreadId defaultTaskHandle;
osThreadId ThreadTask02Handle;
osThreadId ThreadTask03Handle;
osThreadId ThreadTask04Handle;
osThreadId ThreadTask05Handle;
osMessageQId USMARTQueueHandle;

void StartDefaultTask(void const * argument);
void USART1ManageFuc(void const * argument);
void USMARTManageFuc(void const * argument);
void J1939ManageFuc(void const * argument);
void LwipManageFuc(void const * argument);

extern void MX_LWIP_Init(void);
void MX_FREERTOS_Init(void); /* (MISRA C 2004 rule 8.1) */

void MX_FREERTOS_Init(void) {

  /* Create the thread(s) */
  /* definition and creation of defaultTask */
  osThreadDef(defaultTask, StartDefaultTask, osPriorityNormal, 0, 128);
  defaultTaskHandle = osThreadCreate(osThread(defaultTask), NULL);

  /* definition and creation of ThreadTask02 */
  osThreadDef(ThreadTask02, USART1ManageFuc, osPriorityNormal, 0, 128);
  ThreadTask02Handle = osThreadCreate(osThread(ThreadTask02), NULL);

  /* definition and creation of ThreadTask03 */
  osThreadDef(ThreadTask03, USMARTManageFuc, osPriorityIdle, 0, 128);
  ThreadTask03Handle = osThreadCreate(osThread(ThreadTask03), NULL);

  /* definition and creation of ThreadTask04 */
  osThreadDef(ThreadTask04, J1939ManageFuc, osPriorityIdle, 0, 128);
  ThreadTask04Handle = osThreadCreate(osThread(ThreadTask04), NULL);

  /* definition and creation of ThreadTask05 */
  osThreadDef(ThreadTask05, LwipManageFuc, osPriorityIdle, 0, 128);
  ThreadTask05Handle = osThreadCreate(osThread(ThreadTask05), NULL);

  /* Create the queue(s) */
  /* definition and creation of USMARTQueue */
/* what about the sizeof here??? cd native code */
  osMessageQDef(USMARTQueue, 8, usmart_receiveSTR);
  USMARTQueueHandle = osMessageCreate(osMessageQ(USMARTQueue), NULL);

}

void StartDefaultTask(void const * argument)
{
  /* init code for LWIP */
  MX_LWIP_Init();

  /* USER CODE BEGIN StartDefaultTask */
  /* Infinite loop */
  Hal_TimStart_Init();
  // TPAD_Init();
  usmart_init();
  Uart3_DMA_Init();
  Uart4_DMA_Init();
  RTC_WakeUp_Init();
  Ringbuff_init();
  CAN_Filter_Config();
  W25QXX_Init();
  HAL_ADC_Start_DMA(&hadc3, (uint32_t *)&ADC_Conversion[0], SAMPLE_N * ADC_TOTAL_CH_NUM);
  uint16_t w25qxxID = W25QXX_ReadID();
  LOG_PRINTF("W25QXX ID:0x%x \r\n", w25qxxID);
  XmRamInit(); /* 初始化XMRAM */

  for (;;)
  {
    char receive_buf[200];
    memset(receive_buf, 0, sizeof(receive_buf) / sizeof(receive_buf[0]));
    Get_Uart_Data(USART1, receive_buf, sizeof(receive_buf) / sizeof(receive_buf[0]));
    // if(TPAD_Scan(0)){
    //   LED1_Toggle;
    // }
    // delay_ms(150);

    InputCapture();
    // printf("%s\n", receive_buf);
    osDelay(1);
  }
  /* USER CODE END StartDefaultTask */
}

void USART1ManageFuc(void const * argument)
{
  /* USER CODE BEGIN USART1ManageFuc */
  /* Infinite loop */
  for (;;)
  {
    // SetLight0Pwm();
    // delay_ms(1000);
    osDelay(1);
  }
  /* USER CODE END USART1ManageFuc */
}

void USMARTManageFuc(void const * argument)
{
  /* USER CODE BEGIN USMARTManageFuc */
  /* Infinite loop */
  for (;;)
  {
    Remote_control();
    osDelay(1);
  }
  /* USER CODE END USMARTManageFuc */
}

void J1939ManageFuc(void const * argument)
{
  /* USER CODE BEGIN J1939ManageFuc */
  // CAN_Register(GetmessageToRcvbuff, NULL);
  // BMSmanager_Init();
  /* Infinite loop */
  for (;;)
  {
    // GtmgFrRcvbufToPGN();
    // GetmsgconvertToSend();

    // char data[] = {0x01, 0x02, 0x03, 0x04, 0x05, 0x06, 0x07, 0x08, 0x09, 0x0A, 0x0B, 0x0C, 0x0D, 0x0E, 0x0F, 0x11, 0x12};
    // BMS_Send_message(BRM, data);

    // uint8_t Getmsglen = BMS_Get_message(CHM, &(BMSmanager.messageData));
    // LOG_PRINTF("GetCHM message: \r\n");
    // for (uint8_t i = 0; i < 8; i++)
    // {
    //   LOG_PRINTF("0x %x \r\n", BMSmanager.messageData[i]);
    // }
    osDelay(1);
  }
  /* USER CODE END J1939ManageFuc */
}

void LwipManageFuc(void const * argument)
{
  /* USER CODE BEGIN LwipManageFuc */
  tcp_client_connect_config();
  /* Infinite loop */
  for(;;)
  {
    tcp_client_fun();
    osDelay(1);
  }
  /* USER CODE END LwipManageFuc */
}

/************************ (C) COPYRIGHT STMicroelectronics *****END OF FILE****/
